# XHSC_HC32F002 register map
Vendor: XHSC Co.Ltd; Series: ARMCM0P; File version: 1.0
CPU: CM0P r0p0, little endian, no MPU, no FPU, 3 interrupt priority bits
Registers are 32-bit, read-write, reset 0x0 unless marked. A register's access mark holds for its fields unless they carry their own. Offsets are from the block's base; [hi:lo] are bit positions; {n}, {i} and the like mark numbered series.

## BTIM3 — desc BTIM
Base 0x40007400
Same registers: BTIM4 0x40007500, BTIM5 0x40007600
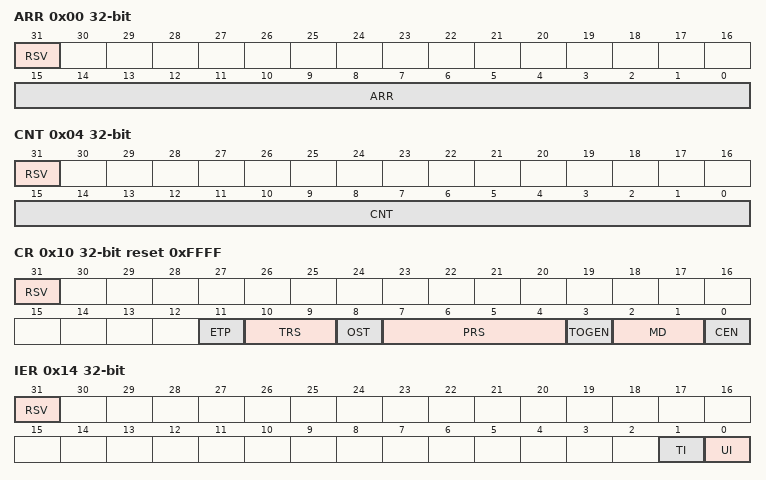
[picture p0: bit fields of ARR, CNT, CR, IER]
0x00 ARR (reset mask 0xFFFF)
  [31] RSV, [15:0] ARR
0x04 CNT (reset mask 0xFFFF)
  [31] RSV, [15:0] CNT
0x10 CR reset 0xFFFF (reset mask 0xFFFF)
  [31] RSV, [11] ETP, [10:9] TRS, [8] OST, [7:4] PRS, [3] TOGEN, [2:1] MD, [0] CEN
0x14 IER (reset mask 0xF)
  [31] RSV, [1] TI, [0] UI
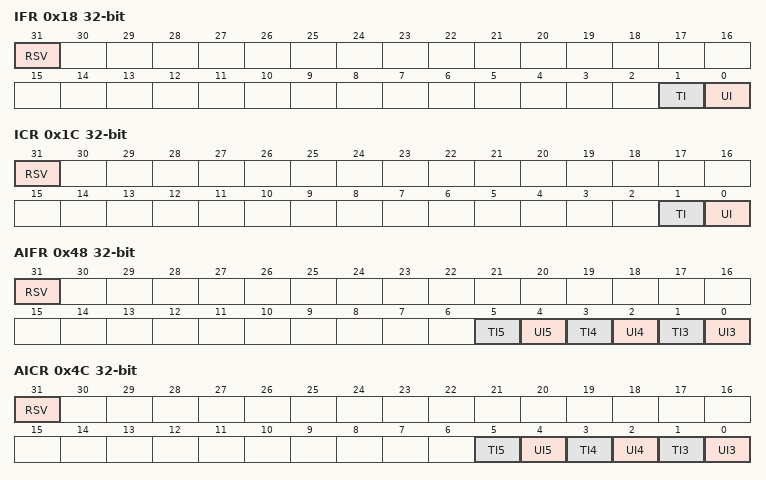
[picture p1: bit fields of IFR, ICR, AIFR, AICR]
0x18 IFR ro (reset mask 0xF)
  [31] RSV, [1] TI, [0] UI
0x1C ICR (reset mask 0xF)
  [31] RSV, [1] TI, [0] UI
0x48 AIFR ro (reset mask 0xF)
  [31] RSV, [5] TI5, [4] UI5, [3] TI4, [2] UI4, [1] TI3, [0] UI3
0x4C AICR (reset mask 0xF)
  [31] RSV, [5] TI5, [4] UI5, [3] TI4, [2] UI4, [1] TI3, [0] UI3

## CTRIM
Base 0x40005000
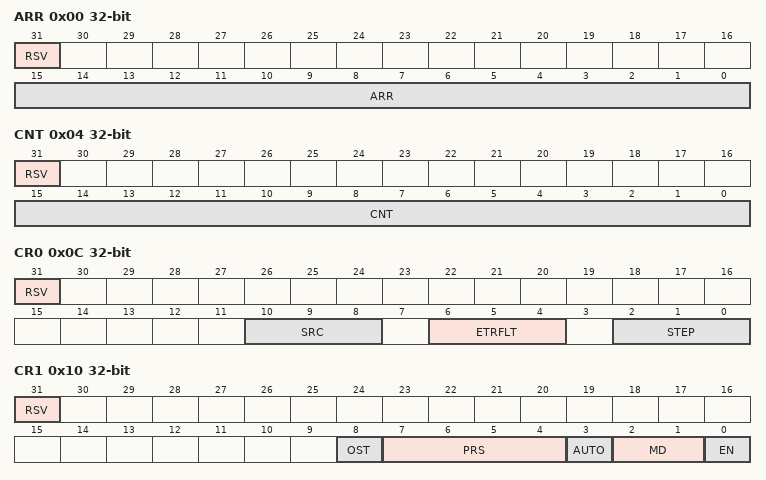
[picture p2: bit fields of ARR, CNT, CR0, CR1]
0x00 ARR (reset mask 0xFFFF)
  [31] RSV, [15:0] ARR
0x04 CNT ro (reset mask 0xFFFF)
  [31] RSV, [15:0] CNT
0x0C CR0 (reset mask 0xFFFF)
  [31] RSV, [10:8] SRC, [6:4] ETRFLT, [2:0] STEP
0x10 CR1 (reset mask 0xFFFF)
  [31] RSV, [8] OST, [7:4] PRS, [3] AUTO, [2:1] MD, [0] EN
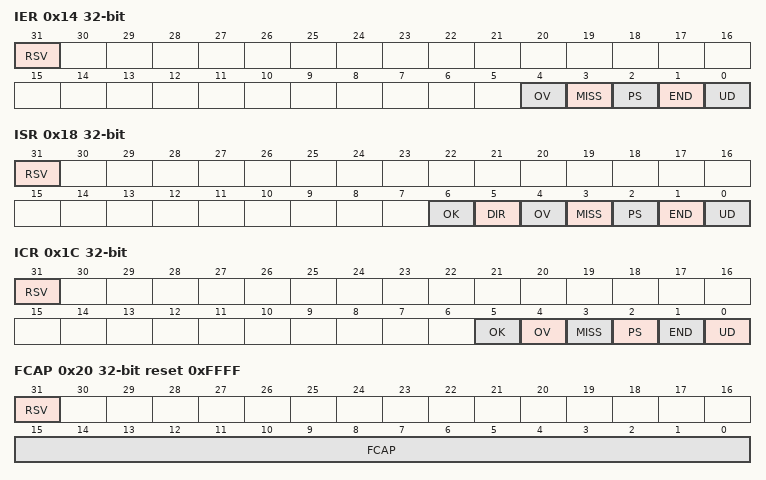
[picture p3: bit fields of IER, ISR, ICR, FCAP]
0x14 IER (reset mask 0xFF)
  [31] RSV, [4] OV, [3] MISS, [2] PS, [1] END, [0] UD
0x18 ISR ro (reset mask 0xFF)
  [31] RSV, [6] OK, [5] DIR, [4] OV, [3] MISS, [2] PS, [1] END, [0] UD
0x1C ICR (reset mask 0xFF)
  [31] RSV, [5] OK, [4] OV, [3] MISS, [2] PS, [1] END, [0] UD
0x20 FCAP ro reset 0xFFFF (reset mask 0xFFFF)
  [31] RSV, [15:0] FCAP
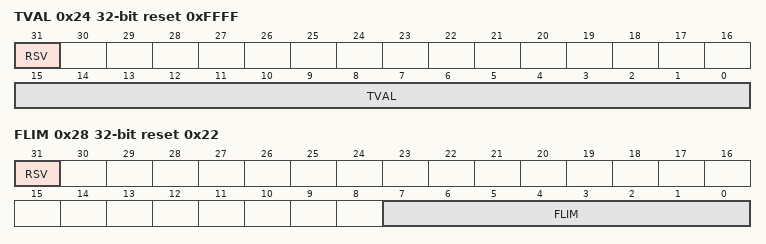
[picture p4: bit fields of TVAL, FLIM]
0x24 TVAL ro reset 0xFFFF (reset mask 0xFFFF)
  [31] RSV, [15:0] TVAL
0x28 FLIM reset 0x22 (reset mask 0xFF)
  [31] RSV, [7:0] FLIM

## FLASH
Base 0x40020000
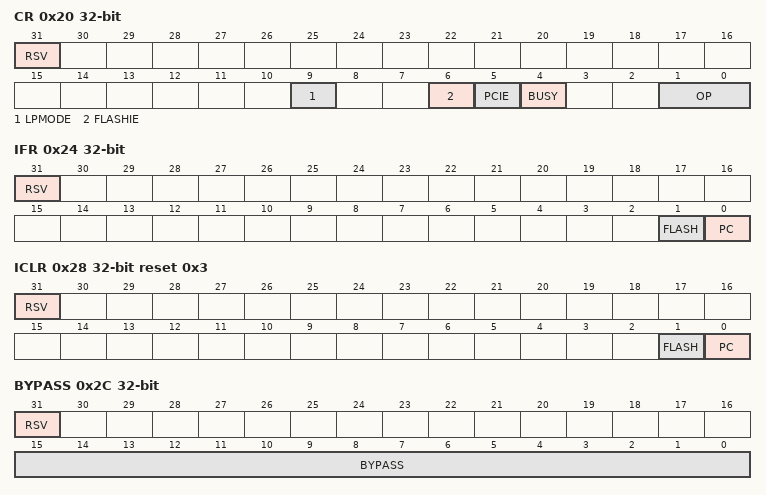
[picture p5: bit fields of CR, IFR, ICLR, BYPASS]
0x20 CR
  [31] RSV, [9] LPMODE, [6] FLASHIE, [5] PCIE, [4] BUSY ro, [1:0] OP
0x24 IFR ro (reset mask 0xFF)
  [31] RSV, [1] FLASH, [0] PC
0x28 ICLR wo reset 0x3
  [31] RSV rw, [1] FLASH rw, [0] PC rw
0x2C BYPASS wo (reset mask 0xFFFF)
  [31] RSV, [15:0] BYPASS
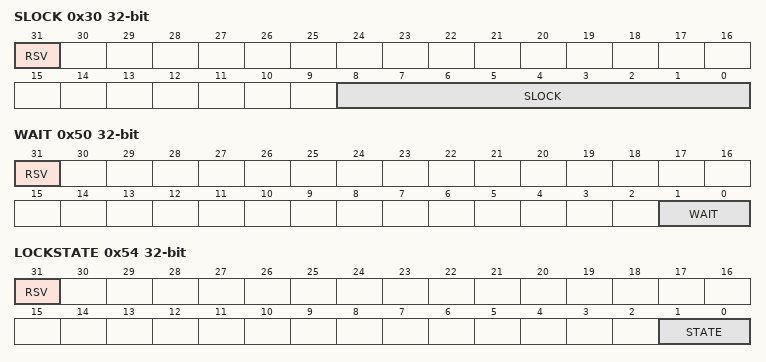
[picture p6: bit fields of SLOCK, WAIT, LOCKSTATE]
0x30 SLOCK
  [31] RSV, [8:0] SLOCK
0x50 WAIT
  [31] RSV, [1:0] WAIT
0x54 LOCKSTATE ro
  [31] RSV, [1:0] STATE

## GPIOA — desc GPIO
Base 0x40020C00
Same registers: GPIOB 0x40020D00, GPIOC 0x40020E00, GPIOD 0x40020F00
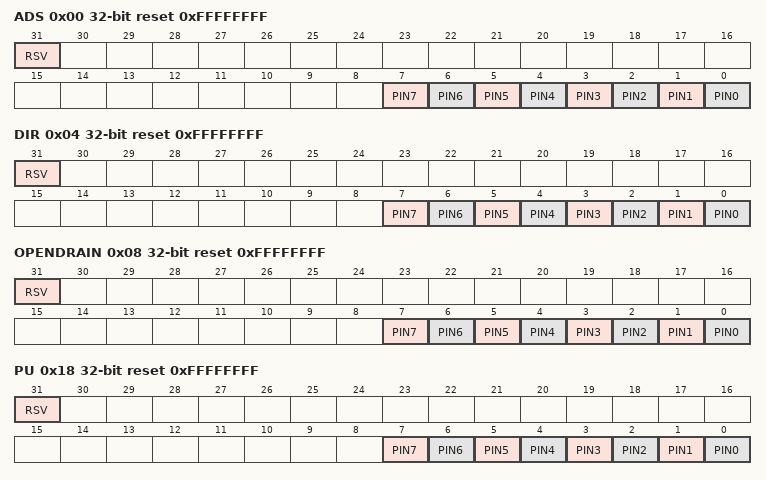
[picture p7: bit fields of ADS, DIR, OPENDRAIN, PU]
0x00 ADS reset 0xFFFFFFFF (reset mask 0xFFFF)
  [31] RSV, [n] PIN{n} (n=0..7)
0x04 DIR reset 0xFFFFFFFF (reset mask 0xFFFF)
  [31] RSV, [n] PIN{n} (n=0..7)
0x08 OPENDRAIN reset 0xFFFFFFFF (reset mask 0xFFFF)
  [31] RSV, [n] PIN{n} (n=0..7)
0x18 PU reset 0xFFFFFFFF (reset mask 0xFFFF)
  [31] RSV, [n] PIN{n} (n=0..7)
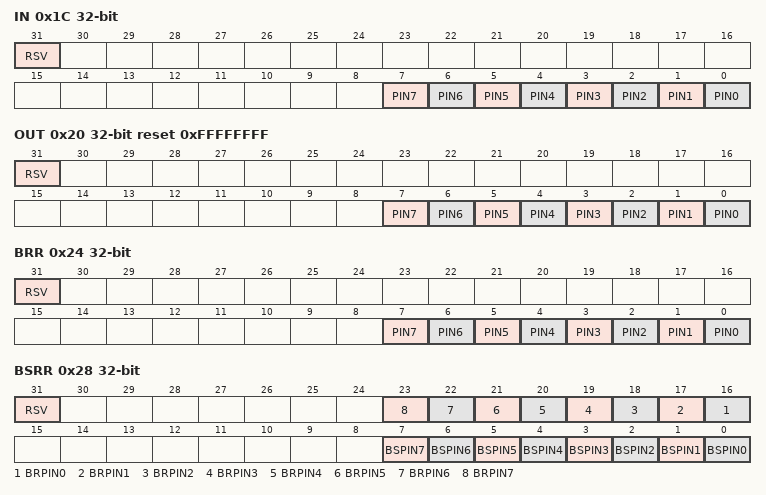
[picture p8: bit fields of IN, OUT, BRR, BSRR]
0x1C IN ro (reset mask 0xFFFF)
  [31] RSV, [n] PIN{n} (n=0..7)
0x20 OUT reset 0xFFFFFFFF (reset mask 0xFFFF)
  [31] RSV, [n] PIN{n} (n=0..7)
0x24 BRR wo (reset mask 0xFFFF)
  [31] RSV, [n] PIN{n} (n=0..7)
0x28 BSRR wo
  [31] RSV, [n+16] BRPIN{n} (n=0..7), [n] BSPIN{n} (n=0..7)
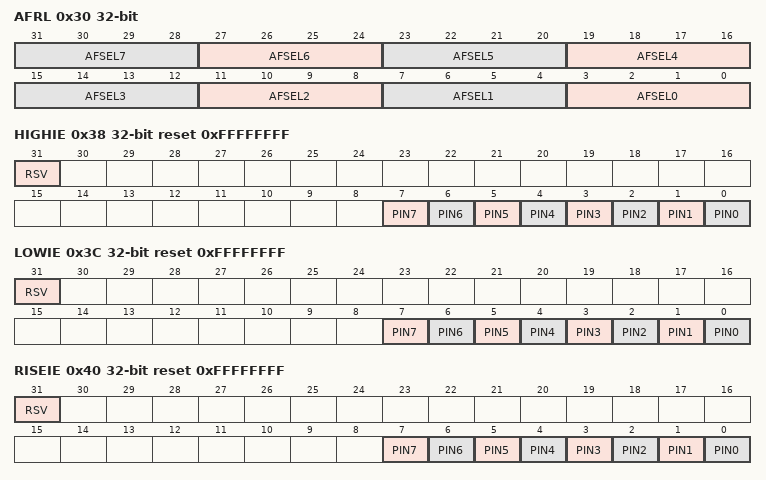
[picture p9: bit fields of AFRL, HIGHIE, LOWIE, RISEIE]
0x30 AFRL
  [4n+3:4n] AFSEL{n} (n=0..7)
0x38 HIGHIE reset 0xFFFFFFFF (reset mask 0xFFFF)
  [31] RSV, [n] PIN{n} (n=0..7)
0x3C LOWIE reset 0xFFFFFFFF (reset mask 0xFFFF)
  [31] RSV, [n] PIN{n} (n=0..7)
0x40 RISEIE reset 0xFFFFFFFF (reset mask 0xFFFF)
  [31] RSV, [n] PIN{n} (n=0..7)
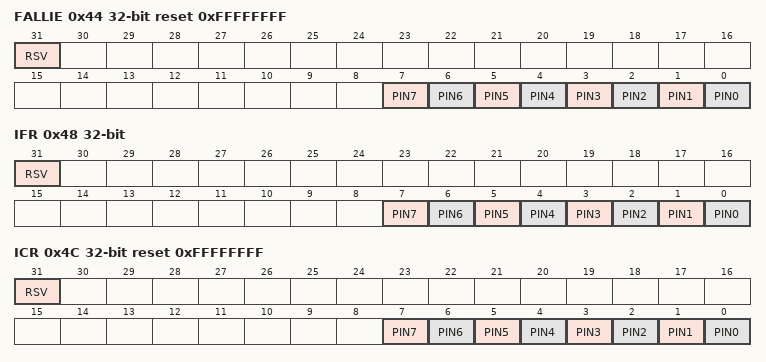
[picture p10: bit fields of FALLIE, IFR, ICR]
0x44 FALLIE reset 0xFFFFFFFF (reset mask 0xFFFF)
  [31] RSV, [n] PIN{n} (n=0..7)
0x48 IFR ro (reset mask 0xFFFF)
  [31] RSV, [n] PIN{n} (n=0..7)
0x4C ICR reset 0xFFFFFFFF (reset mask 0xFFFF)
  [31] RSV, [n] PIN{n} (n=0..7)

## GPIOAUX
Base 0x40020CA0
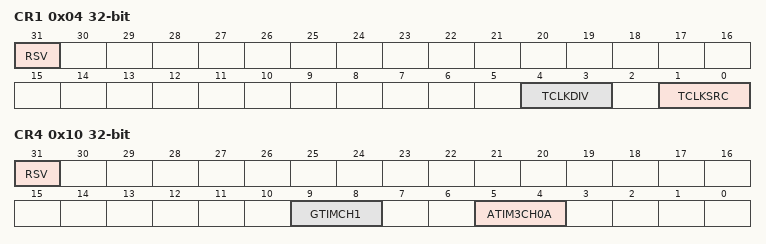
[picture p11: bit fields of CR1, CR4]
0x04 CR1 (reset mask 0xF)
  [31] RSV, [4:3] TCLKDIV, [1:0] TCLKSRC
0x10 CR4
  [31] RSV, [9:8] GTIMCH1, [5:4] ATIM3CH0A

## GTIM
Base 0x40007400; alternate view of BTIM3
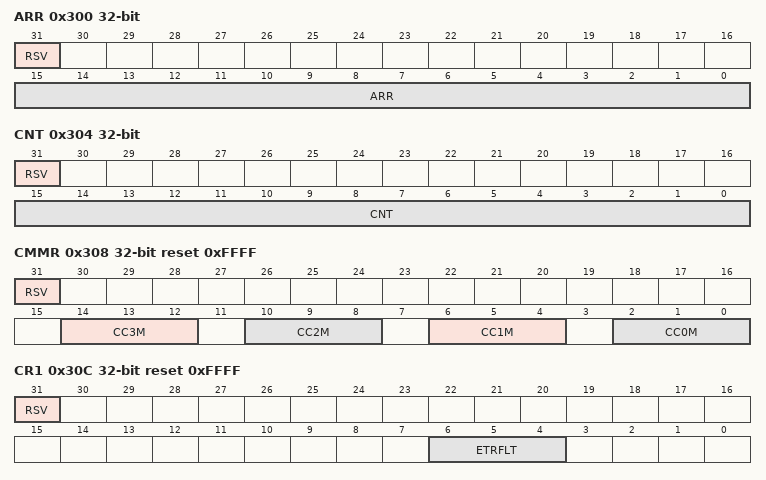
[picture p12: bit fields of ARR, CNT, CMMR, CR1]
0x300 ARR (reset mask 0xFFFF)
  [31] RSV, [15:0] ARR
0x304 CNT (reset mask 0xFFFF)
  [31] RSV, [15:0] CNT
0x308 CMMR reset 0xFFFF (reset mask 0xFFFF)
  [31] RSV, [4n+2:4n] CC{n}M (n=0..3)
0x30C CR1 reset 0xFFFF (reset mask 0xFFFF)
  [31] RSV, [6:4] ETRFLT
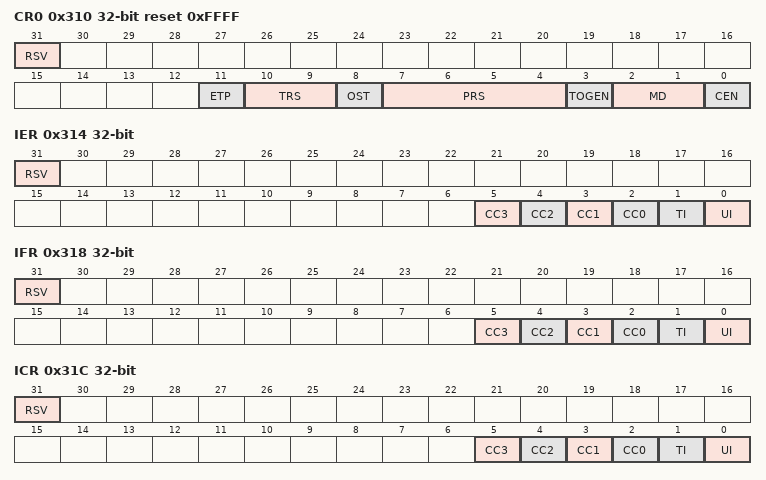
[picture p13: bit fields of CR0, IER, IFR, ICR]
0x310 CR0 reset 0xFFFF (reset mask 0xFFFF)
  [31] RSV, [11] ETP, [10:9] TRS, [8] OST, [7:4] PRS, [3] TOGEN, [2:1] MD, [0] CEN
0x314 IER (reset mask 0xF)
  [31] RSV, [n+2] CC{n} (n=0..3), [1] TI, [0] UI
0x318 IFR (reset mask 0xF)
  [31] RSV, [n+2] CC{n} (n=0..3), [1] TI, [0] UI
0x31C ICR (reset mask 0xF)
  [31] RSV, [n+2] CC{n} (n=0..3), [1] TI, [0] UI
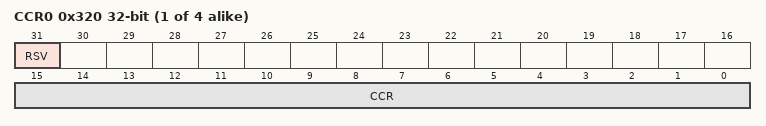
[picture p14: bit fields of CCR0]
{0x320+4i} CCR{i} (reset mask 0xFFFF) (i=0..3)
  [31] RSV, [15:0] CCR
